# TC37XPD register map
Vendor: Infineon; Series: ATVMC; File version: 100
CPU: other r0p0, little endian, MPU, FPU, vendor SysTick, 4 interrupt priority bits
Registers are 32-bit, read-write, reset 0x0 unless marked. A register's access mark holds for its fields unless they carry their own. Offsets are from the block's base; [hi:lo] are bit positions; {n}, {i} and the like mark numbered series.

## HSCT0 — HSCT
Base 0xF0090000
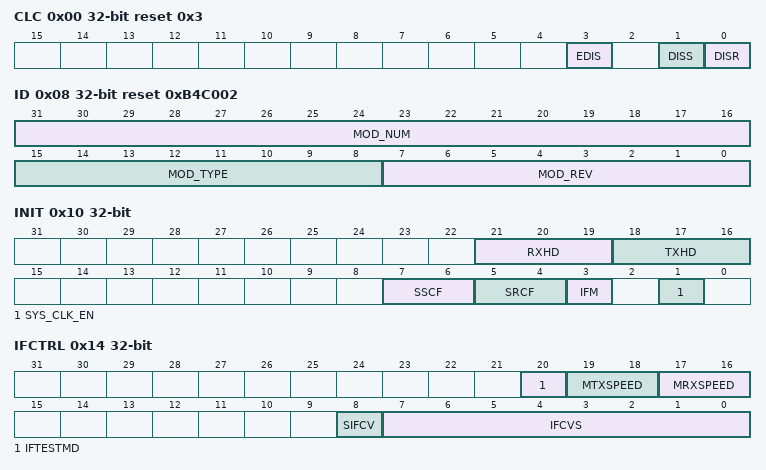
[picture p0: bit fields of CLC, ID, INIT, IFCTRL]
0x00 CLC access per field reset 0x3 — Clock Control Register resetvalue={Application Reset:0x3}
  [3] EDIS rw — Chip System Sleep Mode Control EDIS. The EDIS bit in the CLC register controls whether or not a module is stopped during Chip System initiated Sleep Mode. If EDIS is 0 a Sleep Mode request can be recognized by the module and when received its clock is immediately shut off. Therefore the software has to take care that the HSSL and HSCT communication has been terminated properly before activating the sleep mode request. If EDIS is set to 1 a Sleep Mode request is disregarded by the module and the module continues its operation. Note This chip system sleep mode has nothing to do with the HSCT protocol sleep mode.
  [1] DISS ro — Module Disable Status Bit DISS. Bit indicates the current status of the module and is set after the requested disable is active.
  [0] DISR rw — Module Disable Request Bit DISR. Used for enable disable control clock and local access of the module. This bit switches the clock off immediately therefore the software has to take care that the HSSL and HSCT communication has been terminated properly before setting this bit. The disable is performed after an acknowledge signal from the core logic is received. The acknowledge signal is directly looped back from the request signal.
0x08 ID ro reset 0xB4C002 — Module Identification Register resetvalue={Application Reset:0x0B4C002}
  [31:16] MOD_NUM — Module Number for module identification MOD NUM
  [15:8] MOD_TYPE — Module Number Type MOD TYPE
  [7:0] MOD_REV — Module Revision Number MOD REV
0x10 INIT — Initialization Register resetvalue={Application Reset:0x0}
  [21:19] RXHD — Receive High Speed Divider. RXHD. The Receive High Speed data rate can be reduced by dividing factors. The Receive High Speed data rate is separated from the Transmit High Speed data rate. For future use configuration leads to no output clock pll phase o lt 4 0 gt delivered to the correlator.
  [18:16] TXHD — Transmit High Speed Divider. TXHD. The Transmit High Speed data rate can be reduced by dividing factors. The Transmit High Speed data rate is separated from the Receive High Speed data rate.
  [7:6] SSCF — Select SysClk Frequency Divider SSCF. For master interface defines SysClk pad output frequency. The allowed SysClk frequency is 10MHz or 20MHz.
  [5:4] SRCF — Select Reference Clock Frequency Divider SRCF. Defines physical layer reference frequency PHY CLK and respective input frequency divider. The configuration is valid for Low speed and Medium Speed mode.
  [3] IFM — Select Interface Mode IFM. Select the Interface Mode Master IF or Slave IF .
  [1] SYS_CLK_EN — Enable HSCT SysClk in Master interface SYS CLK EN. SysClk enable activates the SysClk. This feature is only available in the Master interface. In Slave interface mode the register setting does not have an effect.
0x14 IFCTRL access per field — Interface Control Register resetvalue={Application Reset:0x0}
  [20] IFTESTMD rw — Interface TX Test Mode IFTESTMD
  [19:18] MTXSPEED rw — Master Mode TX speed MTXSPEED. Register setting only valid in interface Master mode.
  [17:16] MRXSPEED rw — Master Mode RX speed MRXSPEED. Register setting only valid in interface Master mode.
  [8] SIFCV wo — Master Mode Slave IF control frame trigger SIFCV. Changing the interface configuration software must guarantee not having transfers active on the interface. This register bit always reads back zero.
  [7:0] IFCVS rw — Master Mode Trigger for Interface Control Value to be send to Slave interface IFCVS. See the table quot Interface Control Payload Values quot . Master IF Mode The value is taken as control frame value send as payload to the Slave IF. Slave IF Mode The value is a new configuration of the Slave IF not recommended flow .
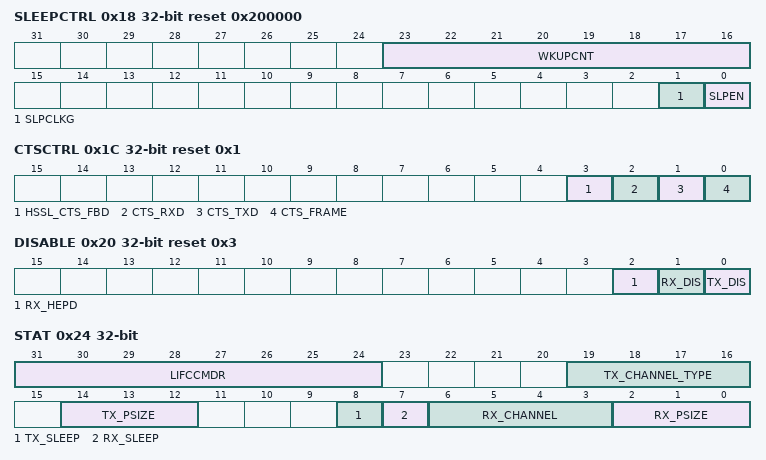
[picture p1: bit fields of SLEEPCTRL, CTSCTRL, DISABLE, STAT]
0x18 SLEEPCTRL reset 0x200000 — Sleep Control Register resetvalue={Application Reset:0x200000}
  [23:16] WKUPCNT — Counter Value for Determining the Wake up Time of the LVDS Line Driver WKUPCNT. This counter value corresponds to wake up time the LVDS requires from sleep to wake up. Counter is clocked by SRI clock.
  [1] SLPCLKG — Clock Gating in Sleep Mode SLPCLKG. In sleep mode the clock for HSCT framer deframer can be gated in order to minimize power consumption. Clock gating Receiving path and transmitting path is separated.
  [0] SLPEN — Sleep mode enabled SLPEN. Sleep mode is enabled and performed after receiving a 1 at the end of a received frame or in transmission direction if no more data to be send.
0x1C CTSCTRL reset 0x1 — Clear To Send Control Register resetvalue={Application Reset:0x1}
  [3] HSSL_CTS_FBD — Disable HSSL interface CTS Frame Blocking HSSL CTS FBD. If this bit is set to 1 CTS signaling is not performed at the interface and the status remains at the clear to send for every frame send.
  [2] CTS_RXD — Disable RX CTS detection CTS RXD. If this bit is set to 1 CTS detection is not performed at the receiver and the status remains internally at clear to send for every frame received.
  [1] CTS_TXD — Disable TX CTS signaling CTS TXD. If this bit is set to 1 CTS signaling is not performed at the interface and the status remains at the clear to send for every frame send.
  [0] CTS_FRAME — Transmit CTS Frame Generation CTS FRAME. Dedicated CTS frames are generated after the receive data path is not able to accept more data. The situation is indicated by the CTS header bit in case there is currently no data to be transferred.
0x20 DISABLE reset 0x3 — Transmission Disable Register resetvalue={Application Reset:0x3}
  [2] RX_HEPD — Disable RX Header Error Discard Payload data. RX HEPD. Instead of discarding the Payload data at a header error the payload data is passed to the higher layer HSSL . Only channel data to HSSL is affected. This function is available in Master and in Slave mode.
  [1] RX_DIS — Disable HSCT Receive path in Master interface RX DIS. Disable the receive line path of the HSCT interface. If this bit is set to 1 no transfer from the other side can be received and the Master RX path is in a low power state. This feature is only available in the Master interface. Slave interface RX path can not be disabled and a write to the register has no effect.
  [0] TX_DIS — Disable HSCT Transmit path in Master interface TX DIS. Disable the transmit path of the HSCT interface. If this bit is set to 1 no transfer can be initiated and the LVDS driver is disabled.
0x24 STAT ro — Status Register resetvalue={Application Reset:0x0}
  [31:24] LIFCCMDR — Last Interface Control Command Received LIFCCMDR. The bit value reflects the last control command received. The bit is active in Slave interface mode only. In Master mode it reflects logic 0 always. See CROSSREFERENCE
  [19:16] TX_CHANNEL_TYPE — Transmission Logical Channel Type TX CHANNEL TYPE. Coding of the logical channel type is according to the Table Logical Channel Type Coding. This value was used in the logical channel type field in the header for the actual transfer in transmit direction.
  [14:12] TX_PSIZE — Transmission Payload Size TX PSIZE. Coding of the logical channel type is according to the Table Payload Size Coding. This value was used in the logical channel type field in the header for the actual transfer in transmit direction.
  [8] TX_SLEEP — TX Transmission Sleep Mode Status TX SLEEP
  [7] RX_SLEEP — RX Receiving Sleep Mode Status RX SLEEP
  [6:3] RX_CHANNEL — RX Receiving Logical Channel Type RX CHANNEL. Contains the logical channel type of the last received frame. See Table quot Logical Channel Type Coding quot .
  [2:0] RX_PSIZE — RX Receiving Payload Size RX PSIZE. Contains the payload size of the last received frame.
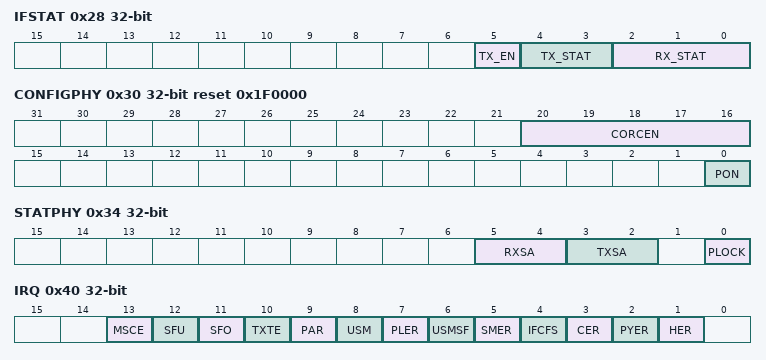
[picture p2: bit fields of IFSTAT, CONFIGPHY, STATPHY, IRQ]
0x28 IFSTAT ro — Interface Status Register resetvalue={Application Reset:0x0}
  [5] TX_EN — HSCT LVDS Slave interface TX enable TX EN. Slave interface only
  [4:3] TX_STAT — HSCT Slave interface Status for TX link TX STAT. Slave interface receiver only
  [2:0] RX_STAT — HSCT Slave interface Status for RX link RX STAT. Slave interface transmitter only
0x30 CONFIGPHY reset 0x1F0000 — Configuration Physical Layer Register resetvalue={Application Reset:0x1F0000}
  [20:16] CORCEN — Correlator phase enable allows to enable disable each of the 5 Phase outputs separately. CORCEN
  [0] PON — Physical Layer Power On. PON
0x34 STATPHY ro — STATPHY resetvalue={Application Reset:0x0}
  [5:4] RXSA — Receiver speed RXSA
  [3:2] TXSA — Transmitter speed TXSA
  [0] PLOCK — PLL locked PLOCK
0x40 IRQ ro — Interrupt register resetvalue={Application Reset:0x0}
  [13] MSCE — Multi Slave scenario Command Error MSCE. This interrupt indicates a control command which is not allowed in multi Slave scenario. In Master and Slave mode a not allowed command results to an error.
  [12] SFU — Synchronization FIFO underflow in TX direction SFU. Controller to Physical layer data synchronization FIFO in TX transfer direction hit an underflow situation. This interrupt is an indication about a to slow SRI clock compared to Physical layer clock which results in a underflow situation. Minimum SRI frequency 40 MHz.
  [11] SFO — Synchronization FIFO overflow in RX direction SFO. Physical layer to Controller data synchronization FIFO in RX transfer direction hit an overflow situation. This interrupt is an indication about a to slow SRI clock compared to Physical layer clock which results in a overflow situation. Minimum SRI frequency 40 MHz.
  [10] TXTE — TX transfer error occurred on a disabled TX channel. TXTE. A disabled TX triggers an error interrupt if TX disabled on a pending or active data transfer. TX CTS configuration change on a active CTS frame.
  [9] PAR — PING Answer Received PAR. The received message was identified as PING.
  [8] USM — Unsolicited Message Received USM. Unsolicited message received indication. Unsolicited message indicates a system event to the other interface side.
  [7] PLER — PLL lost lock error PLER. After the PLL locked the PLL may loose lock which is reflected by the error
  [6] USMSF — Unsolicited message frame send finished USMSF. Interrupt is indicated after the unsolicited message send is finished.
  [5] SMER — Speed Mode Switch Error Master Mode only SMER. Speed mode change did not work. Received PING payload not valid.
  [4] IFCFS — HSCT interface control frame send IFCFS. The scheduled interface control command is send.
  [3] CER — HSCT command error CER. Control command not valid or control payload size bigger than 8 bit. Single Slave specific commands received in Multi Slave Mode do not trigger CER error but only MSCE error.
  [2] PYER — Payload error detected PYER. Payload does not fit the header size
  [1] HER — Header error detected HER. Not supported size Received command at Slave interface 8 bit size only other command sizes generate an error. Received command ping answer at Master interface 32 bit size only other command sizes generate an error Unsolicited data 32 bit only Logical data channel size 8 bit Not supported logical channel type 0b1xxx 0010 Slave interface control and Slave interface read
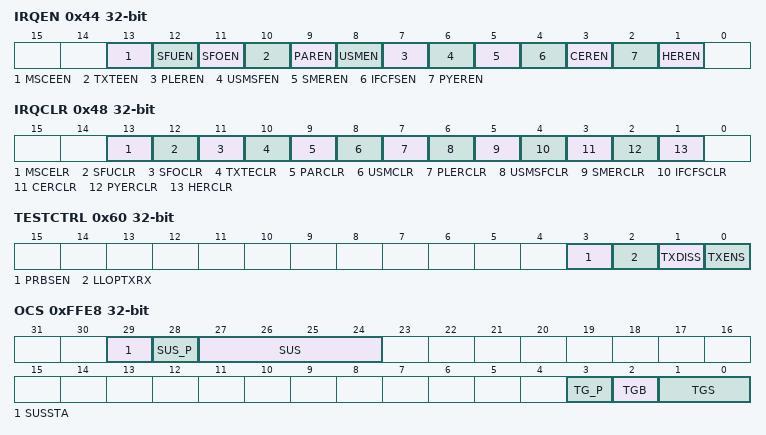
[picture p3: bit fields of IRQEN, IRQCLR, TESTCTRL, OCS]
0x44 IRQEN — Interrupt Enable Register resetvalue={Application Reset:0x0}
  [13] MSCEEN — Multi Slave scenario Command Error interrupt enable MSCEEN
  [12] SFUEN — Synchronization FIFO underflow in TX direction interrupt enable SFUEN
  [11] SFOEN — Synchronization FIFO overflow in RX direction interrupt enable SFOEN
  [10] TXTEEN — TX disable error interrupt enable TXTEEN
  [9] PAREN — PING Answer Received enable PAREN
  [8] USMEN — Unsolicited Message received enable USMEN
  [7] PLEREN — PLL lost lock error interrupt enable PLEREN
  [6] USMSFEN — Unsolicited message frame send finished USMSFEN
  [5] SMEREN — Speed Mode Switch Error interrupt enable SMEREN
  [4] IFCFSEN — HSCT interface control command send enable IFCFSEN
  [3] CEREN — HSCT command error interrupt enable CEREN
  [2] PYEREN — Payload error detected interrupt enable PYEREN
  [1] HEREN — Header error detected interrupt enable HEREN
0x48 IRQCLR wo — Interrupt Clear Register resetvalue={Application Reset:0x0}
  [13] MSCELR — Multi Slave scenario Command Error interrupt clear MSCELR
  [12] SFUCLR — Synchronization FIFO underflow in TX direction interrupt clear SFUCLR
  [11] SFOCLR — Synchronization FIFO overflow in RX direction interrupt clear SFOCLR
  [10] TXTECLR — TX disable error interrupt clear TXTECLR
  [9] PARCLR — PING Answer received clear PARCLR
  [8] USMCLR — Unsolicited Message received clear USMCLR
  [7] PLERCLR — PLL lost lock error interrupt clear PLERCLR
  [6] USMSFCLR — Unsolicited message frame send finished interrupt clear USMSFCLR
  [5] SMERCLR — Speed Mode Switch Error interrupt clear SMERCLR
  [4] IFCFSCLR — HSCT interface control command send interrupt clear IFCFSCLR
  [3] CERCLR — HSCT command error interrupt clear CERCLR
  [2] PYERCLR — Payload error detected interrupt clear PYERCLR
  [1] HERCLR — Header error detected interrupt clear HERCLR
0x50 USMR ro — Unsolicited Status Message Received resetvalue={Application Reset:0x0}
  [31:0] USMR — Unsolicited status message received USMR. The register contains the last received unsolicited status message.
0x54 USMS — Unsolicited Status Message Send resetvalue={Application Reset:0x0}
  [31:0] USMS — Unsolicited status message send USMS. Writing to the register triggers an unsolicited status message to be send to the other interface side.
0x60 TESTCTRL access per field — Test Control Register resetvalue={Application Reset:0x0}
  [3] PRBSEN rw — PRBS Pattern enable PRBSEN. Enable of the PRBSEN bit allows a continuos PRBS stream with the configured transfer speed Baud rate. This feature is available to measure ISI during the time other SoC functions are running in an applicative mode. This feature is for measurement purpose only.
  [2] LLOPTXRX rw — LVDS loop back TX to RX enable LLOPTXRX. Transmit data at LVDS is directly looped back to the LVDS RX. Data transfer speed is defined by the TX speed configuration. The data path in the SoC is using the complete Transmit path through all functional layers and is looped back at LVDS from TX to RX. Also at RX data path all SoC data layers are active. Requires same speed configuration for RX and TX link before enabled.
  [1] TXDISS wo — Disable Slave TX path Slave Interface mode only TXDISS. This function should be only used during interface testing the mode and SW development. In functional mode the Slave interface should only be controlled via transfer commands received from Master interface. This trigger register reads back 0 always. If TXENS and TXDISS are written one TXDISS has higher priority. The status is visible in IFSTAT.TX EN.
  [0] TXENS wo — Enable Slave TX path Slave interface mode only TXENS. This function should be only used during interface testing the mode and SW development. In functional mode the Slave interface should only be controlled via transfer commands received from Master interface. This trigger register reads back 0 always. If TXENS and TXDISS are written one TXDISS has higher priority. The status is visible in IFSTAT.TX EN.
0xFFE8 OCS access per field — OCDS Control and Status resetvalue={Debug Reset:0x0}
  [29] SUSSTA ro — Suspend State SUSSTA
  [28] SUS_P wo — SUS Write Protection SUS P. SUS is only written when SUS P is 1 otherwise unchanged. Read as 0.
  [27:24] SUS rw — OCDS Suspend Control SUS. Controls the sensitivity to the suspend signal coming from the OCDS Trigger Switch OTGS Others 160 160 reserved After a Hard suspend the HSCT and higher layer protocol module must be reset. A a new initialization sequence is required afterwards
  [3] TG_P wo — TGS TGB Write Protection TG P. TGS and TGB are only written when TG P is 1 otherwise unchanged. Read as 0.
  [2] TGB rw — OTGB0 1 Bus Select TGB
  [1:0] TGS rw — Trigger Set for OTGB0 1 TGS. Others 160 160 reserved no Trigger Set selected
0xFFEC KRSTCLR wo — Reset Status Clear Register resetvalue={Application Reset:0x0}
  [0] CLR — Kernel Reset Status Clear CLR. Read always as 0.
0xFFF0 KRST1 — Reset Register 1 resetvalue={Application Reset:0x0}
  [0] RST — Kernel Reset RST. This reset bit can be used to request for a kernel reset. The kernel reset will be executed if the reset bits of both kernel reset registers is set. The RST bit will be cleared re set to 180 0 180 by the BPI FPI after the kernel reset was executed. It is strongly recommended to reset the HSCT and HSSL in sequence to avoid communication issues.
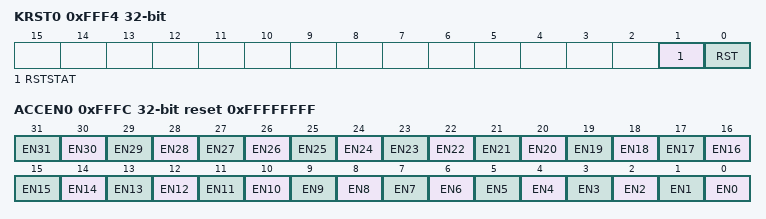
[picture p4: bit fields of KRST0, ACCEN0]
0xFFF4 KRST0 access per field — Reset Register 0 resetvalue={Application Reset:0x0}
  [1] RSTSTAT ro — Kernel Reset Status RSTSTAT. This bit indicates wether a kernel reset was executed or not. This bit is set by the BPI FPI after the execution of a kernel reset in the same clock cycle both reset bits. This bit can be cleared by writing with 180 1 180 to the CLR bit in the related KRSTCLR register.
  [0] RST rw — Kernel Reset RST. This reset bit can be used to request for a kernel reset. The kernel reset will be executed if the reset bits of both kernel registers are set. The RST bit will be cleared re set to 180 0 180 by the BPI FPI after the kernel reset was executed. It is strongly recommended to reset the HSCT and HSSL in sequence to avoid communication issues.
0xFFFC ACCEN0 reset 0xFFFFFFFF — Access Enable Register 0 resetvalue={Application Reset:0x0FFFFFFFF}
  [n] EN{n} (n=0..31) — Access Enable for Master TAG ID 31 EN31. This bit enables read write access to the protected resources for transactions with the Master TAG ID n
